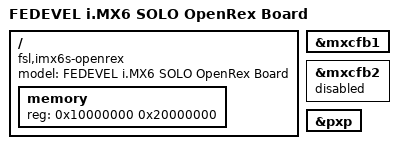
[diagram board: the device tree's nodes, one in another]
/*
 * Copyright 2012 Freescale Semiconductor, Inc.
 * Copyright 2011 Linaro Ltd.
 *
 * The code contained herein is licensed under the GNU General Public
 * License. You may obtain a copy of the GNU General Public License
 * Version 2 or later at the following locations:
 *
 * http://www.opensource.org/licenses/gpl-license.html
 * http://www.gnu.org/copyleft/gpl.html
 */

/dts-v1/;

#include "imx6dl.dtsi"
#include "imx6qdl-openrex.dtsi"

/ {
	model = "FEDEVEL i.MX6 SOLO OpenRex Board";
	compatible = "fsl,imx6s-openrex", "fsl,imx6dl";

	memory {
		reg = <0x10000000 0x20000000>; /* reg = 0x10000000 (base address) 0x20000000 (size = 536870912 bits => 512MB) */
	};
};

&mxcfb1 {
	status = "okay";
};

&mxcfb2 {
	status = "disabled";
};

&pxp {
	status = "okay";
};

